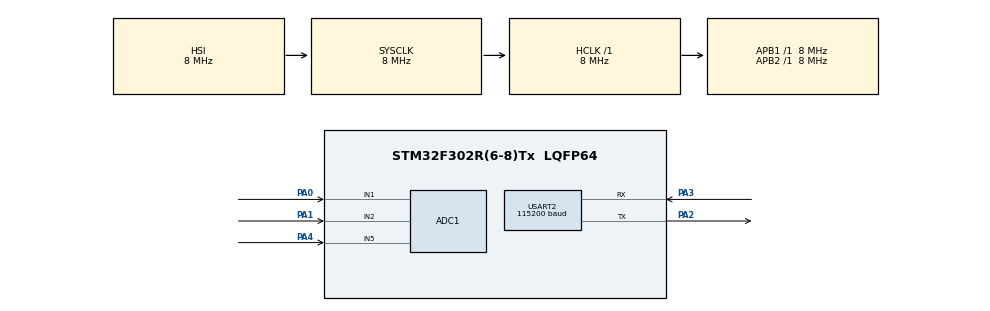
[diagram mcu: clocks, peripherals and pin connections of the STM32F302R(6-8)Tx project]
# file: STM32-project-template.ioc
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ADC1.Channel-10\#ChannelRegularConversion=ADC_CHANNEL_2
ADC1.Channel-11\#ChannelRegularConversion=ADC_CHANNEL_5
ADC1.Channel-9\#ChannelRegularConversion=ADC_CHANNEL_1
ADC1.EnableInjectedConversion=DISABLE
ADC1.EnableRegularConversion=ENABLE
ADC1.NbrOfConversion=3
ADC1.NbrOfConversionFlag=1
ADC1.Offset-10\#ChannelRegularConversion=0
ADC1.Offset-11\#ChannelRegularConversion=0
ADC1.Offset-9\#ChannelRegularConversion=0
ADC1.OffsetNumber-10\#ChannelRegularConversion=ADC_OFFSET_NONE
ADC1.OffsetNumber-11\#ChannelRegularConversion=ADC_OFFSET_NONE
ADC1.OffsetNumber-9\#ChannelRegularConversion=ADC_OFFSET_NONE
ADC1.Rank-10\#ChannelRegularConversion=2
ADC1.Rank-11\#ChannelRegularConversion=3
ADC1.Rank-9\#ChannelRegularConversion=1
ADC1.SamplingTime-10\#ChannelRegularConversion=ADC_SAMPLETIME_19CYCLES_5
ADC1.SamplingTime-11\#ChannelRegularConversion=ADC_SAMPLETIME_19CYCLES_5
ADC1.SamplingTime-9\#ChannelRegularConversion=ADC_SAMPLETIME_19CYCLES_5
ADC1.SequencerNbRanks=3
ADC1.SubFamily=STM32F302x8
ADC1.master=1
Dma.ADC1.0.Direction=DMA_PERIPH_TO_MEMORY
Dma.ADC1.0.Instance=DMA1_Channel1
Dma.ADC1.0.MemDataAlignment=DMA_MDATAALIGN_HALFWORD
Dma.ADC1.0.MemInc=DMA_MINC_ENABLE
Dma.ADC1.0.Mode=DMA_CIRCULAR
Dma.ADC1.0.PeriphDataAlignment=DMA_PDATAALIGN_HALFWORD
Dma.ADC1.0.PeriphInc=DMA_PINC_DISABLE
Dma.ADC1.0.Priority=DMA_PRIORITY_HIGH
Dma.Request0=ADC1
Mcu.Family=STM32F3
Mcu.Name=STM32F302R(6-8)Tx
Mcu.Package=LQFP64
NVIC.DMA1_Channel1_IRQn=true\:0\:0\:false\:false\:true\:false\:true\:true
NVIC.PriorityGroup=NVIC_PRIORITYGROUP_4
PA0.Mode=IN1-Single-Ended
PA0.Signal=ADC1_IN1
PA1.Mode=IN2-Single-Ended
PA1.Signal=ADC1_IN2
PA13.Mode=Serial_Wire
PA13.Signal=SYS_JTMS-SWDIO
PA14.Mode=Serial_Wire
PA14.Signal=SYS_JTCK-SWCLK
PA2.Mode=Asynchronous
PA2.Signal=USART2_TX
PA3.Mode=Asynchronous
PA3.Signal=USART2_RX
PA4.Mode=IN5-Single-Ended
PA4.Signal=ADC1_IN5
ProjectManager.HeapSize=0x400
ProjectManager.StackSize=0x400
ProjectManager.TargetToolchain=Makefile
RCC.AHBFreq_Value=8000000
RCC.APB1Freq_Value=8000000
RCC.APB2Freq_Value=8000000
RCC.CortexFreq_Value=8000000
RCC.HSE_VALUE=8000000
RCC.HSI_VALUE=8000000
RCC.LSE_VALUE=32768
RCC.PLLMUL=RCC_PLL_MUL4
RCC.SYSCLKFreq_VALUE=8000000
RCC.USBFreq_Value=16000000
USART2.BaudRate=115200
USART2.VirtualMode-Asynchronous=VM_ASYNC
VP_ADC1_TempSens_Input.Mode=IN-TempSens
VP_ADC1_Vref_Input.Mode=IN-Vrefint
board=custom

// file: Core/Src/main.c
/* USER CODE BEGIN Header */
/**
 ******************************************************************************
 * @file           : main.c
 * @brief          : Main program body
 ******************************************************************************
 */
/* USER CODE END Header */
#include "main.h"
#include "adc.h"
#include "dma.h"
#include "usart.h"
#include "gpio.h"

/* USER CODE BEGIN Includes */
#include <Project/projectMain.h>
#include <stdint.h>
/* USER CODE END Includes */

void SystemClock_Config(void);

int main(void)
{

  /* MCU Configuration--------------------------------------------------------*/

  /* Reset of all peripherals, Initializes the Flash interface and the Systick. */
  HAL_Init();

  /* Configure the system clock */
  SystemClock_Config();

  /* Initialize all configured peripherals */
  MX_GPIO_Init();
  MX_DMA_Init();
  MX_ADC1_Init();
  MX_USART2_UART_Init();
  /* USER CODE BEGIN 2 */
    projectMain();
  /* USER CODE END 2 */

  /* Infinite loop */
    while (1) {

    }
}

void SystemClock_Config(void)
{
  RCC_OscInitTypeDef RCC_OscInitStruct = {0};
  RCC_ClkInitTypeDef RCC_ClkInitStruct = {0};
  RCC_PeriphCLKInitTypeDef PeriphClkInit = {0};

  /** Initializes the RCC Oscillators according to the specified parameters
  * in the RCC_OscInitTypeDef structure.
  */
  RCC_OscInitStruct.OscillatorType = RCC_OSCILLATORTYPE_HSI;
  RCC_OscInitStruct.HSIState = RCC_HSI_ON;
  RCC_OscInitStruct.HSICalibrationValue = RCC_HSICALIBRATION_DEFAULT;
  RCC_OscInitStruct.PLL.PLLState = RCC_PLL_ON;
  RCC_OscInitStruct.PLL.PLLSource = RCC_PLLSOURCE_HSI;
  RCC_OscInitStruct.PLL.PLLMUL = RCC_PLL_MUL4;
  if (HAL_RCC_OscConfig(&RCC_OscInitStruct) != HAL_OK)
  {
    Error_Handler();
  }

  /** Initializes the CPU, AHB and APB buses clocks
  */
  RCC_ClkInitStruct.ClockType = RCC_CLOCKTYPE_HCLK|RCC_CLOCKTYPE_SYSCLK
                              |RCC_CLOCKTYPE_PCLK1|RCC_CLOCKTYPE_PCLK2;
  RCC_ClkInitStruct.SYSCLKSource = RCC_SYSCLKSOURCE_HSI;
  RCC_ClkInitStruct.AHBCLKDivider = RCC_SYSCLK_DIV1;
  RCC_ClkInitStruct.APB1CLKDivider = RCC_HCLK_DIV1;
  RCC_ClkInitStruct.APB2CLKDivider = RCC_HCLK_DIV1;

  if (HAL_RCC_ClockConfig(&RCC_ClkInitStruct, FLASH_LATENCY_0) != HAL_OK)
  {
    Error_Handler();
  }
  PeriphClkInit.PeriphClockSelection = RCC_PERIPHCLK_ADC1;
  PeriphClkInit.Adc1ClockSelection = RCC_ADC1PLLCLK_DIV1;

  if (HAL_RCCEx_PeriphCLKConfig(&PeriphClkInit) != HAL_OK)
  {
    Error_Handler();
  }
}

void Error_Handler(void)
{
    __disable_irq();
}
